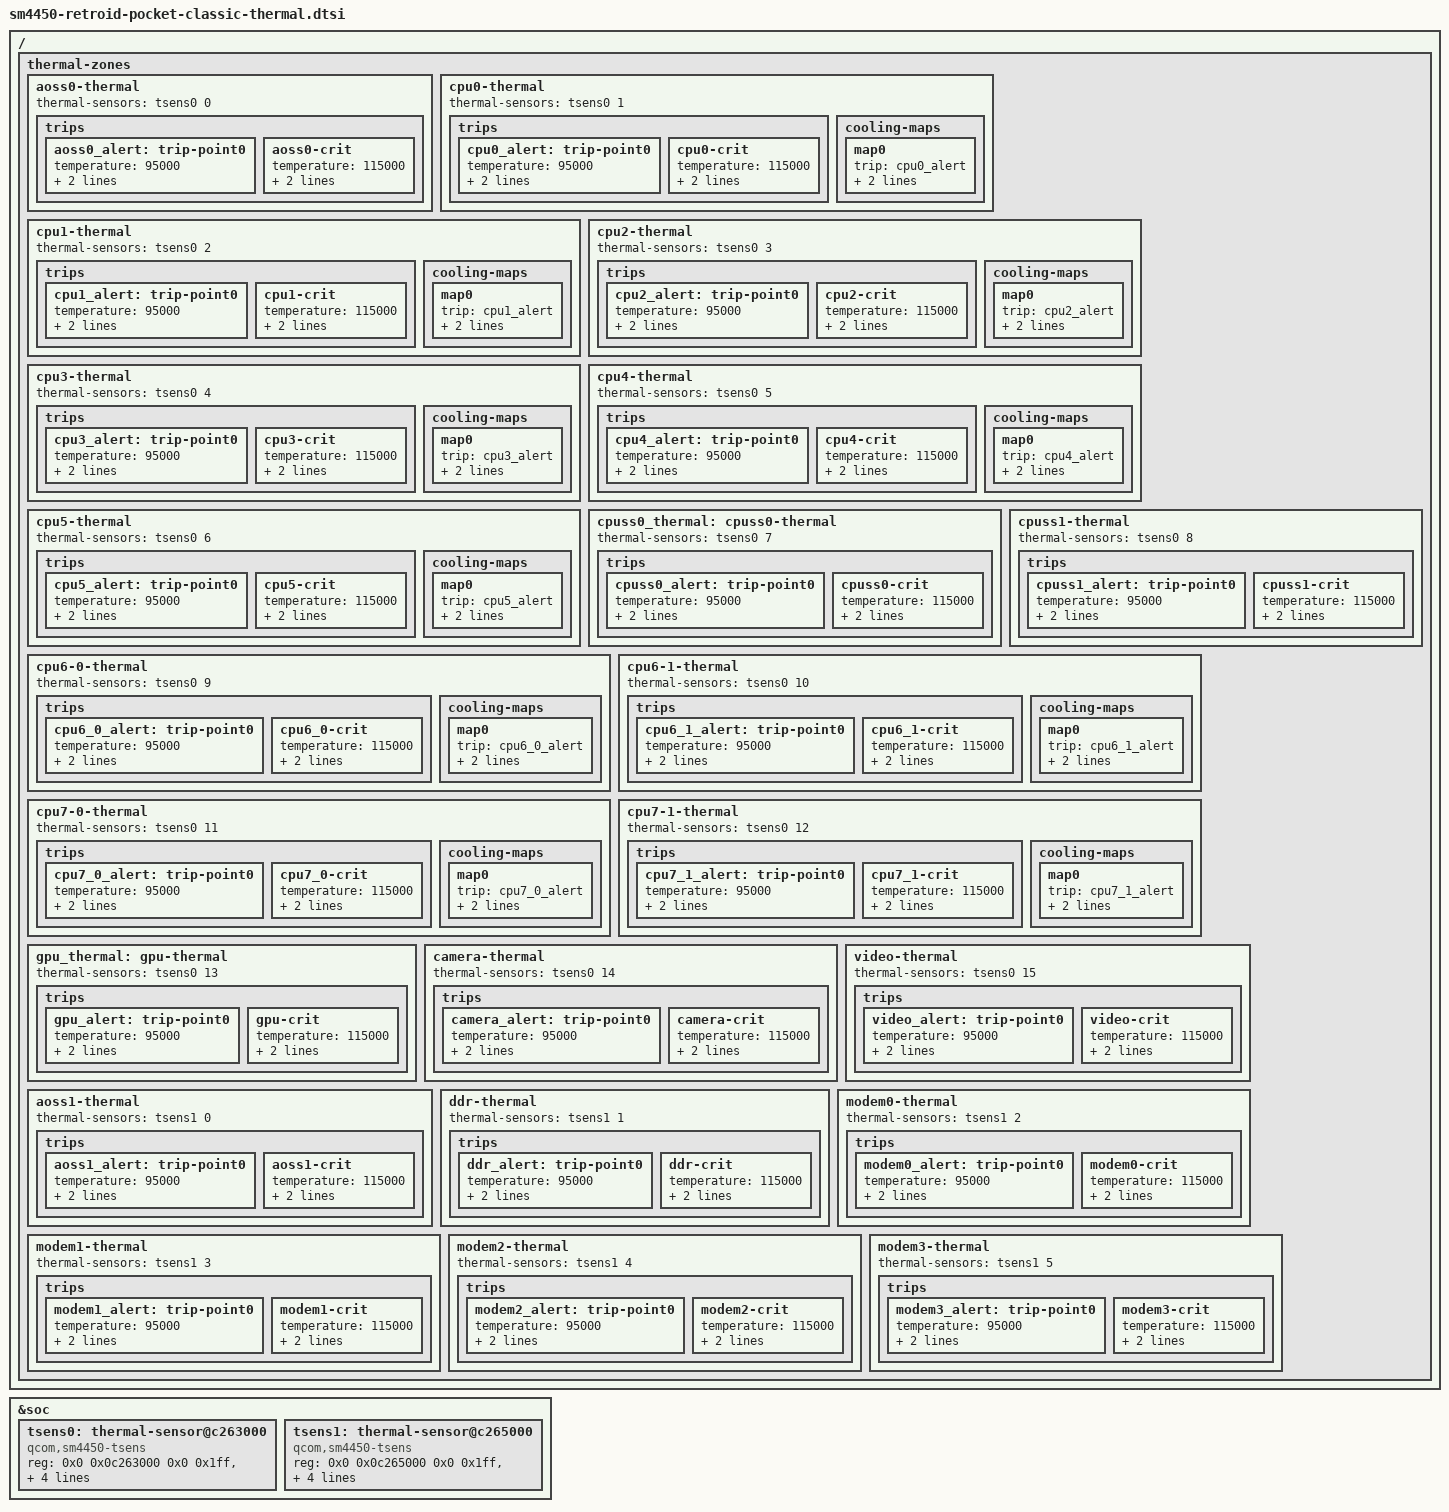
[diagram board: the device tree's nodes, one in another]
// SPDX-License-Identifier: BSD-3-Clause
/*
 * Copyright (C) 2026-present ROCKNIX (https://github.com/ROCKNIX).
 *
 * Retroid Pocket Classic (SM4450 "parrot"): thermal.
 * Maintained by Banana as its own description of this handheld (it started as ROCKNIX's tree).
 *
 * The two TSENS controllers and the thermal zones on them: trip points, CPU and GPU cooling.
 * The fan's curve on the CPU and GPU zones is per board revision, in the .dts files.
 *
 * Included from sm4450-retroid-pocket-classic-common.dtsi; do not include it on its own.
 */

&soc {
	tsens0: thermal-sensor@c263000 {
		compatible = "qcom,sm4450-tsens", "qcom,tsens-v2";
		reg = <0x0 0x0c263000 0x0 0x1ff>,
		      <0x0 0x0c222000 0x0 0x8>;
		#qcom,sensors = <16>;
		interrupts = <GIC_SPI 506 IRQ_TYPE_LEVEL_HIGH>,
			     <GIC_SPI 508 IRQ_TYPE_LEVEL_HIGH>;
		interrupt-names = "uplow", "critical";
		#thermal-sensor-cells = <1>;
	};

	tsens1: thermal-sensor@c265000 {
		compatible = "qcom,sm4450-tsens", "qcom,tsens-v2";
		reg = <0x0 0x0c265000 0x0 0x1ff>,
		      <0x0 0x0c223000 0x0 0x8>;
		#qcom,sensors = <6>;
		interrupts = <GIC_SPI 507 IRQ_TYPE_LEVEL_HIGH>,
			     <GIC_SPI 509 IRQ_TYPE_LEVEL_HIGH>;
		interrupt-names = "uplow", "critical";
		#thermal-sensor-cells = <1>;
	};
};

/ {
	thermal-zones {
		aoss0-thermal {
			thermal-sensors = <&tsens0 0>;

			trips {
				aoss0_alert: trip-point0 {
					temperature = <95000>;
					hysteresis = <2000>;
					type = "passive";
				};

				aoss0-crit {
					temperature = <115000>;
					hysteresis = <0>;
					type = "critical";
				};
			};
		};

		cpu0-thermal {
			thermal-sensors = <&tsens0 1>;

			trips {
				cpu0_alert: trip-point0 {
					temperature = <95000>;
					hysteresis = <2000>;
					type = "passive";
				};

				cpu0-crit {
					temperature = <115000>;
					hysteresis = <0>;
					type = "critical";
				};
			};

			cooling-maps {
				map0 {
					trip = <&cpu0_alert>;
					cooling-device = <&cpu0 THERMAL_NO_LIMIT THERMAL_NO_LIMIT>;
				};
			};
		};

		cpu1-thermal {
			thermal-sensors = <&tsens0 2>;

			trips {
				cpu1_alert: trip-point0 {
					temperature = <95000>;
					hysteresis = <2000>;
					type = "passive";
				};

				cpu1-crit {
					temperature = <115000>;
					hysteresis = <0>;
					type = "critical";
				};
			};

			cooling-maps {
				map0 {
					trip = <&cpu1_alert>;
					cooling-device = <&cpu1 THERMAL_NO_LIMIT THERMAL_NO_LIMIT>;
				};
			};
		};

		cpu2-thermal {
			thermal-sensors = <&tsens0 3>;

			trips {
				cpu2_alert: trip-point0 {
					temperature = <95000>;
					hysteresis = <2000>;
					type = "passive";
				};

				cpu2-crit {
					temperature = <115000>;
					hysteresis = <0>;
					type = "critical";
				};
			};

			cooling-maps {
				map0 {
					trip = <&cpu2_alert>;
					cooling-device = <&cpu2 THERMAL_NO_LIMIT THERMAL_NO_LIMIT>;
				};
			};
		};

		cpu3-thermal {
			thermal-sensors = <&tsens0 4>;

			trips {
				cpu3_alert: trip-point0 {
					temperature = <95000>;
					hysteresis = <2000>;
					type = "passive";
				};

				cpu3-crit {
					temperature = <115000>;
					hysteresis = <0>;
					type = "critical";
				};
			};

			cooling-maps {
				map0 {
					trip = <&cpu3_alert>;
					cooling-device = <&cpu3 THERMAL_NO_LIMIT THERMAL_NO_LIMIT>;
				};
			};
		};

		cpu4-thermal {
			thermal-sensors = <&tsens0 5>;

			trips {
				cpu4_alert: trip-point0 {
					temperature = <95000>;
					hysteresis = <2000>;
					type = "passive";
				};

				cpu4-crit {
					temperature = <115000>;
					hysteresis = <0>;
					type = "critical";
				};
			};

			cooling-maps {
				map0 {
					trip = <&cpu4_alert>;
					cooling-device = <&cpu4 THERMAL_NO_LIMIT THERMAL_NO_LIMIT>;
				};
			};
		};

		cpu5-thermal {
			thermal-sensors = <&tsens0 6>;

			trips {
				cpu5_alert: trip-point0 {
					temperature = <95000>;
					hysteresis = <2000>;
					type = "passive";
				};

				cpu5-crit {
					temperature = <115000>;
					hysteresis = <0>;
					type = "critical";
				};
			};

			cooling-maps {
				map0 {
					trip = <&cpu5_alert>;
					cooling-device = <&cpu5 THERMAL_NO_LIMIT THERMAL_NO_LIMIT>;
				};
			};
		};

		cpuss0_thermal: cpuss0-thermal {
			thermal-sensors = <&tsens0 7>;

			trips {
				cpuss0_alert: trip-point0 {
					temperature = <95000>;
					hysteresis = <2000>;
					type = "passive";
				};

				cpuss0-crit {
					temperature = <115000>;
					hysteresis = <0>;
					type = "critical";
				};
			};
		};

		cpuss1-thermal {
			thermal-sensors = <&tsens0 8>;

			trips {
				cpuss1_alert: trip-point0 {
					temperature = <95000>;
					hysteresis = <2000>;
					type = "passive";
				};

				cpuss1-crit {
					temperature = <115000>;
					hysteresis = <0>;
					type = "critical";
				};
			};
		};

		cpu6-0-thermal {
			thermal-sensors = <&tsens0 9>;

			trips {
				cpu6_0_alert: trip-point0 {
					temperature = <95000>;
					hysteresis = <2000>;
					type = "passive";
				};

				cpu6_0-crit {
					temperature = <115000>;
					hysteresis = <0>;
					type = "critical";
				};
			};

			cooling-maps {
				map0 {
					trip = <&cpu6_0_alert>;
					cooling-device = <&cpu6 THERMAL_NO_LIMIT THERMAL_NO_LIMIT>;
				};
			};
		};

		cpu6-1-thermal {
			thermal-sensors = <&tsens0 10>;

			trips {
				cpu6_1_alert: trip-point0 {
					temperature = <95000>;
					hysteresis = <2000>;
					type = "passive";
				};

				cpu6_1-crit {
					temperature = <115000>;
					hysteresis = <0>;
					type = "critical";
				};
			};

			cooling-maps {
				map0 {
					trip = <&cpu6_1_alert>;
					cooling-device = <&cpu6 THERMAL_NO_LIMIT THERMAL_NO_LIMIT>;
				};
			};
		};

		cpu7-0-thermal {
			thermal-sensors = <&tsens0 11>;

			trips {
				cpu7_0_alert: trip-point0 {
					temperature = <95000>;
					hysteresis = <2000>;
					type = "passive";
				};

				cpu7_0-crit {
					temperature = <115000>;
					hysteresis = <0>;
					type = "critical";
				};
			};

			cooling-maps {
				map0 {
					trip = <&cpu7_0_alert>;
					cooling-device = <&cpu7 THERMAL_NO_LIMIT THERMAL_NO_LIMIT>;
				};
			};
		};

		cpu7-1-thermal {
			thermal-sensors = <&tsens0 12>;

			trips {
				cpu7_1_alert: trip-point0 {
					temperature = <95000>;
					hysteresis = <2000>;
					type = "passive";
				};

				cpu7_1-crit {
					temperature = <115000>;
					hysteresis = <0>;
					type = "critical";
				};
			};

			cooling-maps {
				map0 {
					trip = <&cpu7_1_alert>;
					cooling-device = <&cpu7 THERMAL_NO_LIMIT THERMAL_NO_LIMIT>;
				};
			};
		};

		gpu_thermal: gpu-thermal {
			thermal-sensors = <&tsens0 13>;

			trips {
				gpu_alert: trip-point0 {
					temperature = <95000>;
					hysteresis = <2000>;
					type = "passive";
				};

				gpu-crit {
					temperature = <115000>;
					hysteresis = <0>;
					type = "critical";
				};
			};
		};

		camera-thermal {
			thermal-sensors = <&tsens0 14>;

			trips {
				camera_alert: trip-point0 {
					temperature = <95000>;
					hysteresis = <2000>;
					type = "passive";
				};

				camera-crit {
					temperature = <115000>;
					hysteresis = <0>;
					type = "critical";
				};
			};
		};

		video-thermal {
			thermal-sensors = <&tsens0 15>;

			trips {
				video_alert: trip-point0 {
					temperature = <95000>;
					hysteresis = <2000>;
					type = "passive";
				};

				video-crit {
					temperature = <115000>;
					hysteresis = <0>;
					type = "critical";
				};
			};
		};

		aoss1-thermal {
			thermal-sensors = <&tsens1 0>;

			trips {
				aoss1_alert: trip-point0 {
					temperature = <95000>;
					hysteresis = <2000>;
					type = "passive";
				};

				aoss1-crit {
					temperature = <115000>;
					hysteresis = <0>;
					type = "critical";
				};
			};
		};

		ddr-thermal {
			thermal-sensors = <&tsens1 1>;

			trips {
				ddr_alert: trip-point0 {
					temperature = <95000>;
					hysteresis = <2000>;
					type = "passive";
				};

				ddr-crit {
					temperature = <115000>;
					hysteresis = <0>;
					type = "critical";
				};
			};
		};

		modem0-thermal {
			thermal-sensors = <&tsens1 2>;

			trips {
				modem0_alert: trip-point0 {
					temperature = <95000>;
					hysteresis = <2000>;
					type = "passive";
				};

				modem0-crit {
					temperature = <115000>;
					hysteresis = <0>;
					type = "critical";
				};
			};
		};

		modem1-thermal {
			thermal-sensors = <&tsens1 3>;

			trips {
				modem1_alert: trip-point0 {
					temperature = <95000>;
					hysteresis = <2000>;
					type = "passive";
				};

				modem1-crit {
					temperature = <115000>;
					hysteresis = <0>;
					type = "critical";
				};
			};
		};

		modem2-thermal {
			thermal-sensors = <&tsens1 4>;

			trips {
				modem2_alert: trip-point0 {
					temperature = <95000>;
					hysteresis = <2000>;
					type = "passive";
				};

				modem2-crit {
					temperature = <115000>;
					hysteresis = <0>;
					type = "critical";
				};
			};
		};

		modem3-thermal {
			thermal-sensors = <&tsens1 5>;

			trips {
				modem3_alert: trip-point0 {
					temperature = <95000>;
					hysteresis = <2000>;
					type = "passive";
				};

				modem3-crit {
					temperature = <115000>;
					hysteresis = <0>;
					type = "critical";
				};
			};
		};
	};
};
